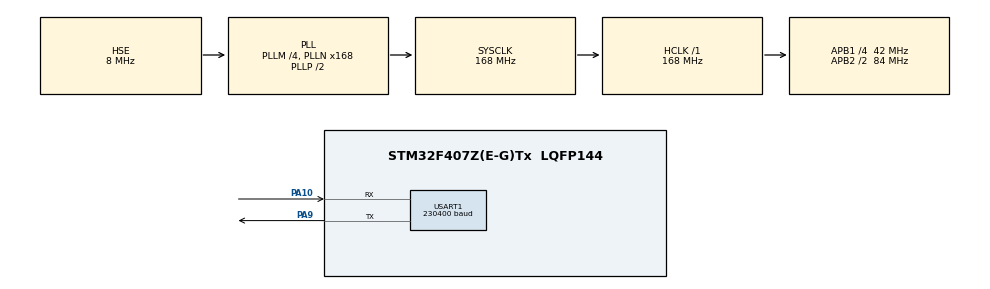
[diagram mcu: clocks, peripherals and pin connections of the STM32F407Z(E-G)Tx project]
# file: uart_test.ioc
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Mcu.Family=STM32F4
Mcu.Name=STM32F407Z(E-G)Tx
Mcu.Package=LQFP144
NVIC.PriorityGroup=NVIC_PRIORITYGROUP_4
PA10.Mode=Asynchronous
PA10.Signal=USART1_RX
PA9.Mode=Asynchronous
PA9.Signal=USART1_TX
PH0-OSC_IN.Mode=HSE-External-Oscillator
PH0-OSC_IN.Signal=RCC_OSC_IN
PH1-OSC_OUT.Mode=HSE-External-Oscillator
PH1-OSC_OUT.Signal=RCC_OSC_OUT
ProjectManager.HeapSize=0x200
ProjectManager.StackSize=0x400
ProjectManager.TargetToolchain=MDK-ARM V5.32
RCC.48MHZClocksFreq_Value=84000000
RCC.AHBFreq_Value=168000000
RCC.APB1CLKDivider=RCC_HCLK_DIV4
RCC.APB1Freq_Value=42000000
RCC.APB1TimFreq_Value=84000000
RCC.APB2CLKDivider=RCC_HCLK_DIV2
RCC.APB2Freq_Value=84000000
RCC.APB2TimFreq_Value=168000000
RCC.CortexFreq_Value=168000000
RCC.HCLKFreq_Value=168000000
RCC.HSE_VALUE=8000000
RCC.HSI_VALUE=16000000
RCC.LSE_VALUE=32768
RCC.PLLM=4
RCC.PLLN=168
RCC.PLLSourceVirtual=RCC_PLLSOURCE_HSE
RCC.SYSCLKFreq_VALUE=168000000
RCC.SYSCLKSource=RCC_SYSCLKSOURCE_PLLCLK
RCC.VCOOutputFreq_Value=336000000
USART1.BaudRate=230400
USART1.Mode=MODE_TX
USART1.VirtualMode=VM_ASYNC
board=custom

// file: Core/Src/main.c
/* USER CODE BEGIN Header */
/**
  ******************************************************************************
  * @file           : main.c
  * @brief          : Main program body
  ******************************************************************************
  * @attention
  *
  * Copyright (c) 2026 STMicroelectronics.
  * All rights reserved.
  *
  * This software is licensed under terms that can be found in the LICENSE file
  * in the root directory of this software component.
  * If no LICENSE file comes with this software, it is provided AS-IS.
  *
  ******************************************************************************
  */
/* USER CODE END Header */
#include "main.h"
#include "usart.h"
#include "gpio.h"
#include "stm32f4xx_hal.h"

void SystemClock_Config(void);
/* USER CODE BEGIN PFP */

// 发送单个字节
// UART send byte (blocking)
static void UART1_SendByte(uint8_t byte)
{
    HAL_UART_Transmit(&huart1, &byte, 1, 0xFFFF);
}

// Generic command frame sender
static void FPGA_Send_Cmd(uint8_t cmd, uint32_t data)
{
    uint8_t buf[7];

    buf[0] = 0xA5;
    buf[1] = cmd;
    buf[2] = (data >>  0) & 0xFF;
    buf[3] = (data >>  8) & 0xFF;
    buf[4] = (data >> 16) & 0xFF;
    buf[5] = (data >> 24) & 0xFF;
    buf[6] = buf[0] ^ buf[1] ^ buf[2] ^ buf[3] ^ buf[4] ^ buf[5];

    for (uint8_t i = 0; i < 7; i++)
    {
        UART1_SendByte(buf[i]);
    }
}

// Set DDS frequency
void FPGA_Send_Freq(uint32_t freq_word)
{
    FPGA_Send_Cmd(0x01, freq_word);
}

// Set DDS amplitude, permille=0~1000 => 0.0%~100.0%
void FPGA_Set_Amp(uint16_t permille)
{
    uint32_t amp;

    if (permille > 1000)
        permille = 1000;

    amp = ((uint32_t)permille * 1024 + 500) / 1000;
    FPGA_Send_Cmd(0x03, amp);
}

void delay_ms(uint32_t ms)
{
    // 推荐直接用HAL_Delay(ms); 这里保留你的循环写法也可以
    uint32_t i, j;
    for(i = 0; i < ms; i++)
        for(j = 0; j < 7200; j++);
}

/* USER CODE END PFP */

int main(void)
{

  /* MCU Configuration--------------------------------------------------------*/

  /* Reset of all peripherals, Initializes the Flash interface and the Systick. */
  HAL_Init();

  /* Configure the system clock */
  SystemClock_Config();

  /* Initialize all configured peripherals */
  MX_GPIO_Init();
  MX_USART1_UART_Init();

  /* Infinite loop */
  while (1)
  {
    FPGA_Send_Freq(260301);         // 10kHz
    FPGA_Set_Amp(1000);             // 100%
    HAL_Delay(2000);
    FPGA_Set_Amp(500);              // 50%
    HAL_Delay(2000);
    FPGA_Set_Amp(250);              // 25%
    HAL_Delay(2000);
  }
}

void SystemClock_Config(void)
{
  RCC_OscInitTypeDef RCC_OscInitStruct = {0};
  RCC_ClkInitTypeDef RCC_ClkInitStruct = {0};

  /** Configure the main internal regulator output voltage
  */
  __HAL_RCC_PWR_CLK_ENABLE();
  __HAL_PWR_VOLTAGESCALING_CONFIG(PWR_REGULATOR_VOLTAGE_SCALE1);

  /** Initializes the RCC Oscillators according to the specified parameters
  * in the RCC_OscInitTypeDef structure.
  */
  RCC_OscInitStruct.OscillatorType = RCC_OSCILLATORTYPE_HSE;
  RCC_OscInitStruct.HSEState = RCC_HSE_ON;
  RCC_OscInitStruct.PLL.PLLState = RCC_PLL_ON;
  RCC_OscInitStruct.PLL.PLLSource = RCC_PLLSOURCE_HSE;
  RCC_OscInitStruct.PLL.PLLM = 4;
  RCC_OscInitStruct.PLL.PLLN = 168;
  RCC_OscInitStruct.PLL.PLLP = RCC_PLLP_DIV2;
  RCC_OscInitStruct.PLL.PLLQ = 4;
  if (HAL_RCC_OscConfig(&RCC_OscInitStruct) != HAL_OK)
  {
    Error_Handler();
  }

  /** Initializes the CPU, AHB and APB buses clocks
  */
  RCC_ClkInitStruct.ClockType = RCC_CLOCKTYPE_HCLK|RCC_CLOCKTYPE_SYSCLK
                              |RCC_CLOCKTYPE_PCLK1|RCC_CLOCKTYPE_PCLK2;
  RCC_ClkInitStruct.SYSCLKSource = RCC_SYSCLKSOURCE_PLLCLK;
  RCC_ClkInitStruct.AHBCLKDivider = RCC_SYSCLK_DIV1;
  RCC_ClkInitStruct.APB1CLKDivider = RCC_HCLK_DIV4;
  RCC_ClkInitStruct.APB2CLKDivider = RCC_HCLK_DIV2;

  if (HAL_RCC_ClockConfig(&RCC_ClkInitStruct, FLASH_LATENCY_5) != HAL_OK)
  {
    Error_Handler();
  }
}

void Error_Handler(void)
{
  __disable_irq();
  while (1)
  {
  }
}
